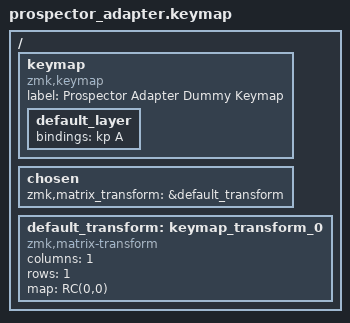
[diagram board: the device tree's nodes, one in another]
#include <dt-bindings/zmk/matrix_transform.h>


/ {
    keymap {
        compatible = "zmk,keymap";
        label = "Prospector Adapter Dummy Keymap";

        default_layer {
            bindings = <&kp A>;
        };
    };
};

/ {
    chosen {
        zmk,matrix_transform = &default_transform;
    };

    default_transform: keymap_transform_0 {
        compatible = "zmk,matrix-transform";
        columns = <1>;
        rows = <1>;
        map = <RC(0,0)>;
    };
};
